VERSION ""

NS_ :

BS_:

BU_: XXX

BO_ 177 FRONT_WHEEL_SPEED: 6 XXX
 SG_ FRONT_RIGHT_WHEEL_SPEED : 7|16@0+ (0.01,0) [0|65535] "kph" XXX
 SG_ FRONT_LEFT_WHEEL_SPEED : 23|16@0+ (0.01,0) [0|65535] "kph" XXX
 SG_ NEW_SIGNAL_1 : 7|16@0+ (1,0) [0|65535] "" XXX

BO_ 179 REAR_WHEEL_SPEED: 6 XXX
 SG_ REAR_RIGHT_WHEEL_SPEED : 7|16@0+ (0.01,0) [0|65535] "kph" XXX
 SG_ REAR_LEFT_WHEEL_SPEED : 23|16@0+ (0.01,0) [0|65535] "kph" XXX

BO_ 970 SPEED: 5 XXX
 SG_ SPEED : 23|8@0+ (1,0) [0|255] "kph" XXX

BO_ 973 BATTERY_3: 5 XXX
 SG_ BATTERY_VOLTAGE : 23|16@0+ (1,0) [0|65535] "V" XXX

BO_ 1324 COOLANT_TEMP: 2 XXX
 SG_ ENGINE_COOLANT_TEMP : 15|8@0+ (0.5,0) [0|255] "degC" XXX

BO_ 59 BATTERY_1: 8 XXX
 SG_ BATTERY_VOLTAGE : 23|16@0+ (1,0) [0|65535] "V" XXX
 SG_ BATTERY_CURRENT : 3|12@0- (0.1,0) [-256|254] "A" XXX

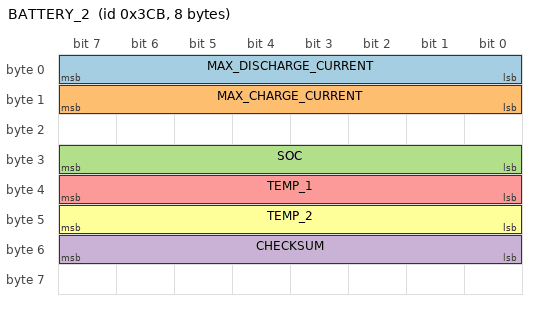
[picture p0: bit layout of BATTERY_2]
BO_ 971 BATTERY_2: 8 XXX
 SG_ MAX_DISCHARGE_CURRENT : 7|8@0+ (1,0) [0|255] "A" XXX
 SG_ MAX_CHARGE_CURRENT : 15|8@0+ (1,0) [0|255] "A" XXX
 SG_ SOC : 31|8@0+ (0.5,0) [0|255] "" XXX
 SG_ CHECKSUM : 55|8@0+ (1,0) [0|255] "" XXX
 SG_ TEMP_1 : 39|8@0- (1,0) [0|255] "" XXX
 SG_ TEMP_2 : 47|8@0- (1,0) [0|255] "" XXX

BO_ 34 ACC_Y: 8 XXX
 SG_ ACC_Y : 7|16@0- (1,-500) [0|65535] "" XXX

BO_ 560 BRAKE_MODULE: 7 XXX
 SG_ BRAKE_PRESSED : 26|1@0+ (1,0) [0|1] "" XXX
 SG_ BRAKE_PEDAL_POS : 47|8@0+ (0.78125,0) [0|100] "%" XXX

BO_ 37 STEERING: 8 XXX
 SG_ STEERING_ANGLE : 3|12@0- (1.5,0) [-500|500] "deg" XXX

BO_ 56 NEW_MSG_1: 8 XXX

BO_ 968 ICE: 6 XXX
 SG_ TARGET_RPM : 23|16@0+ (0.125,0) [0|65535] "" XXX

BO_ 35 ACC_X: 8 XXX
 SG_ ACC_X : 7|16@0+ (1,0) [0|65535] "" XXX

BO_ 57 ENGINE_TEMP: 4 XXX
 SG_ ENGINE_TEMP : 23|8@0+ (1,0) [0|255] "degC" XXX

BO_ 975 NEW_MSG_2: 8 XXX
 SG_ NEW_SIGNAL_1 : 7|16@0+ (1,0) [0|65535] "" XXX

BO_ 1444 NEW_MSG_3: 8 XXX

BO_ 48 BRAKE_PEDAL: 8 XXX
 SG_ BRAKE_PEDAL : 39|8@0+ (0.78125,0) [0|255] "%" XXX

CM_ SG_ 59 BATTERY_CURRENT "positive values are discharge, negative are charge";
CM_ SG_ 57 ENGINE_TEMP "not coolant";
